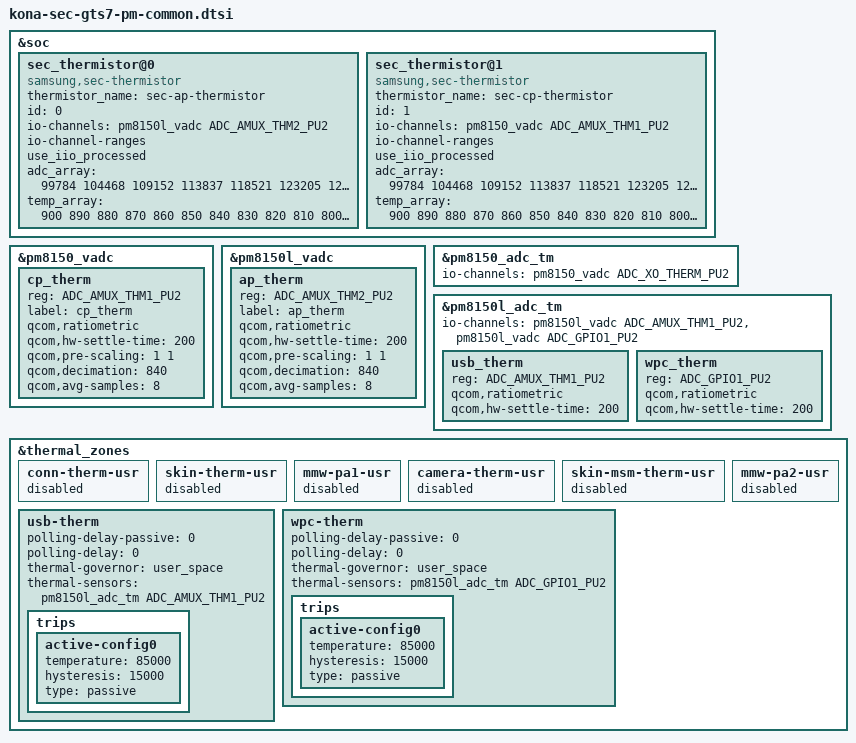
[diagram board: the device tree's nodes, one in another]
/* Copyright (c) 2014, The Linux Foundation. All rights reserved.
 *
 * This program is free software; you can redistribute it and/or modify
 * it under the terms of the GNU General Public License version 2 and
 * only version 2 as published by the Free Software Foundation.
 *
 * This program is distributed in the hope that it will be useful,
 * but WITHOUT ANY WARRANTY; without even the implied warranty of
 * MERCHANTABILITY or FITNESS FOR A PARTICULAR PURPOSE.  See the
 * GNU General Public License for more details.
 */

#include <dt-bindings/regulator/qcom,rpmh-regulator-levels.h>

&soc {
/* AP Thermistor table */
	sec_thermistor@0 {
		compatible = "samsung,sec-thermistor";
		status = "okay";
		thermistor_name = "sec-ap-thermistor";
		id = <0>;

		io-channels = <&pm8150l_vadc ADC_AMUX_THM2_PU2>;
		io-channel-names = "ap_therm";
		io-channel-ranges;
		use_iio_processed;

		adc_array = <99784 104468 109152 113837 118521 123205 127889 132573 137258 141942
				146626 152296 157967 163637 169308 174978 181258 187538 193819 200099
				206379 214671 222962 231254 239545 247837 255648 263460 271271 279083
				286894 299480 312067 324653 337240 349826 361452 373079 384705 396332
				407958 423023 438088 453152 468217 483282 500228 517175 534121 551068
				568014 592331 616647 640964 665280 689597 702780 715964 729147 742331
				755514 775743 795972 816202 836431 856660 880964 905268 929571 953875
				978179 1000523 1022867 1045212 1067556 1089900 1111038 1132175 1153313 1174450
				1195588 1215142 1234697 1254251 1273806 1293360 1312434 1331509 1350583 1369658
				1388732
				1407197 1425661 1444126 1462590 1481055 1498053 1515051 1532050 1549048 1566046
				1579074 1592102 1605129 1618157 1631185 1642033 1652880 1663728 1674575 1685423>;

		temp_array = <900 890 880 870 860 850 840 830 820 810
				800 790 780 770 760 750 740 730 720 710
				700 690 680 670 660 650 640 630 620 610
				600 590 580 570 560 550 540 530 520 510
				500 490 480 470 460 450 440 430 420 410
				400 390 380 370 360 350 340 330 320 310
				300 290 280 270 260 250 240 230 220 210
				200 190 180 170 160 150 140 130 120 110
				100 90 80 70 60 50 40 30 20 10
				0
				(-10) (-20) (-30) (-40) (-50) (-60) (-70) (-80) (-90) (-100)
				(-110)(-120)(-130)(-140)(-150)(-160)(-170)(-180)(-190) (-200)>;
	};

	/* CP Thermistor table */
	sec_thermistor@1 {
		compatible = "samsung,sec-thermistor";
		status = "okay";
		thermistor_name = "sec-cp-thermistor";
		id = <1>;

		io-channels = <&pm8150_vadc ADC_AMUX_THM1_PU2>;
		io-channel-names = "cp_therm";
		io-channel-ranges;
		use_iio_processed;

		adc_array = <99784 104468 109152 113837 118521 123205 127889 132573 137258 141942
				146626 152296 157967 163637 169308 174978 181258 187538 193819 200099
				206379 214671 222962 231254 239545 247837 255648 263460 271271 279083
				286894 299480 312067 324653 337240 349826 361452 373079 384705 396332
				407958 423023 438088 453152 468217 483282 500228 517175 534121 551068
				568014 592331 616647 640964 665280 689597 702780 715964 729147 742331
				755514 775743 795972 816202 836431 856660 880964 905268 929571 953875
				978179 1000523 1022867 1045212 1067556 1089900 1111038 1132175 1153313 1174450
				1195588 1215142 1234697 1254251 1273806 1293360 1312434 1331509 1350583 1369658
				1388732
				1407197 1425661 1444126 1462590 1481055 1498053 1515051 1532050 1549048 1566046
				1579074 1592102 1605129 1618157 1631185 1642033 1652880 1663728 1674575 1685423>;

		temp_array = <900 890 880 870 860 850 840 830 820 810
				800 790 780 770 760 750 740 730 720 710
				700 690 680 670 660 650 640 630 620 610
				600 590 580 570 560 550 540 530 520 510
				500 490 480 470 460 450 440 430 420 410
				400 390 380 370 360 350 340 330 320 310
				300 290 280 270 260 250 240 230 220 210
				200 190 180 170 160 150 140 130 120 110
				100 90 80 70 60 50 40 30 20 10
				0
				(-10) (-20) (-30) (-40) (-50) (-60) (-70) (-80) (-90) (-100)
				(-110)(-120)(-130)(-140)(-150)(-160)(-170)(-180)(-190) (-200)>;
	};
};

&pm8150_vadc {
	/delete-node/ skin_therm;
	cp_therm {
		reg = <ADC_AMUX_THM1_PU2>;
		label = "cp_therm";
		qcom,ratiometric;
		qcom,hw-settle-time = <200>;
		qcom,pre-scaling = <1 1>;
		qcom,decimation = <840>;
		qcom,avg-samples = <8>;
	};
};

&pm8150l_vadc {
	/delete-node/ skin_msm_therm;
	ap_therm {
		reg = <ADC_AMUX_THM2_PU2>;
		label = "ap_therm";
		qcom,ratiometric;
		qcom,hw-settle-time = <200>;
		qcom,pre-scaling = <1 1>;
		qcom,decimation = <840>;
		qcom,avg-samples = <8>;
	};
};

&pm8150_adc_tm {
	io-channels = <&pm8150_vadc ADC_XO_THERM_PU2>;
	/delete-node/ skin_therm@4d;
	/delete-node/ pa_therm1@4e;
};

&pm8150l_adc_tm {
	io-channels = <&pm8150l_vadc ADC_AMUX_THM1_PU2>,
			<&pm8150l_vadc ADC_GPIO1_PU2>;

	/delete-node/ camera_flash_therm@4d;
	/delete-node/ skin_msm_therm@4e;
	/delete-node/ pa_therm2@4f;

	usb_therm {
		reg = <ADC_AMUX_THM1_PU2>;
		qcom,ratiometric;
		qcom,hw-settle-time = <200>;
	};

	wpc_therm {
		reg = <ADC_GPIO1_PU2>;
		qcom,ratiometric;
		qcom,hw-settle-time = <200>;
	};
};

&thermal_zones {
	conn-therm-usr {
		status = "disabled"; 
	};
	skin-therm-usr {
		status = "disabled"; 
	};
	mmw-pa1-usr {
		status = "disabled"; 
	};
	camera-therm-usr {
		status = "disabled"; 
	};
	skin-msm-therm-usr {
		status = "disabled";
	};
	mmw-pa2-usr {
		status = "disabled"; 
	};

	usb-therm {
		polling-delay-passive = <0>;
		polling-delay = <0>;
		thermal-governor = "user_space";
		thermal-sensors = <&pm8150l_adc_tm ADC_AMUX_THM1_PU2>;
		trips {
			active-config0 {
				temperature = <85000>;
				hysteresis = <15000>;
				type = "passive";
			};
		};
	};

	wpc-therm {
		polling-delay-passive = <0>;
		polling-delay = <0>;
		thermal-governor = "user_space";
		thermal-sensors = <&pm8150l_adc_tm ADC_GPIO1_PU2>;
		trips {
			active-config0 {
				temperature = <85000>;
				hysteresis = <15000>;
				type = "passive";
			};
		};
	};
};
